# I2C3 register map
Vendor: Texas Instruments
Peripheral module from a debugger description file (folder TDA2Px).
Registers are 16-bit, access per field, reset 0x0 unless marked. A register's access mark holds for its fields unless they carry their own. Offsets are as the file gives them; lines under a group give offsets from that group; [hi:lo] are bit positions; {n}, {i} and the like mark numbered series; 'fields as' and 'values as' point back to an identical list; <NAME> marks a mode.

## I2C3
0x00 I2C_REVNB_LO ro reset not defined — Module Revision Identifier Used by software to track features, bugs, and compatibility
  [15:0] REVISION — IP Revision
0x04 I2C_REVNB_HI ro reset not defined — Module Revision Identifeir Used by software to track features, bugs, and compatibility
  [15:0] REVISION — IP Revision
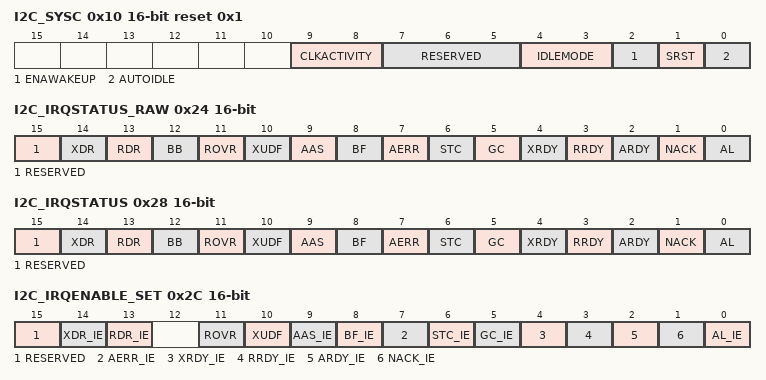
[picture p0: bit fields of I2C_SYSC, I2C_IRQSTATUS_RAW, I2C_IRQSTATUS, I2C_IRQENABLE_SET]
0x10 I2C_SYSC reset 0x1 — System Configuration register
  [9:8] CLKACTIVITY rw — Clock Activity selection bits
    0=boothoff (Both clocks can be cut off); 1=ocpon (Only OCP clock must be kept active; system clock can be cut off); 2=boothon (Only system clock must be kept active; OCP clock can be cut off); 3=syson (Both clocks must be kept active)
  [7:5] RESERVED ro — Reads return 0.
  [4:3] IDLEMODE rw — Idle Mode selection bits
    0=smartidle (Force Idle mode); 1=smartidle_wakeup (No Idle mode); 2=smartidle_wakeup (Smart Idle mode); 3=Smart-idle wakeup-capable mode
  [2] ENAWAKEUP rw — Enable Wakeup control bit
    0=disable (Wakeup mechanism is disabled); 1=enable (Wakeup mechanism is enabled)
  [1] SRST rw — SoftReset bit
    0=nmode (Normal mode); 1=rstmode (The module is reset)
  [0] AUTOIDLE rw — Autoidle bit
    0=disable (Auto Idle mechanism is disabled); 1=enable (Auto Idle mechanism is enabled)
0x20 I2C_EOI — End Of Interrupt number specification
  [0] LINE_NUMBER wo — Software End Of Interrupt (EOI) control. Write number of interrupt output.
0x24 I2C_IRQSTATUS_RAW — Per-event raw interrupt status vector. The raw status is set even if event is not enabled. Write 1 to set the (raw) status. Used mostly for debug
  [15] RESERVED rw — Write 0s for future compatibility. Read returns 0.
  [14] XDR rw — Transmit draining IRQ status.
    0=clear (Transmit draining inactive.); 1=set (Transmit draining enabled.)
  [13] RDR rw — Receive draining IRQ status.
    0=clear (Receive draining inactive.); 1=set (Receive draining enabled.)
  [12] BB ro — Bus busy status. Writing into this bit has no effect.
    1=set (Bus is occupied.); 0=clear (Bus is free.)
  [11] ROVR rw — Receive overrun status. Writing into this bit has no effect.
    1=set (Receiver overrun.); 0=clear (Normal operation.)
  [10] XUDF rw — Transmit underflow status. Writing into this bit has no effect.
    1=set (Transmit underflow.); 0=clear (Normal operation.)
  [9] AAS rw — Address recognized as slave IRQ status.
    0=clear (No action.); 1=set (Address recognized.)
  [8] BF rw — Bus Free IRQ status.
    0=clear (No action.); 1=set (Bus Free.)
  [7] AERR rw — Access Error IRQ status.
    0=clear (No action.); 1=set (Access Error.)
  [6] STC rw — Start Condition IRQ status.
    0=clear (No action.); 1=set (Start Condition detected.)
  [5] GC rw — General call IRQ status. Set to 1 by core when General call address detected and interrupt signaled to IRQ_Crossbar.
    0=clear (No general call detected.); 1=set (General call address detected.)
  [4] XRDY rw — Transmit data ready IRQ status. Set to 1 by core when transmitter and when new data is requested. When set to 1 by core, an interrupt is signaled to IRQ_Crossbar.
    0=clear (Transmision ongoing.); 1=set (Transmit data ready.)
  [3] RRDY rw — Receive data ready IRQ status. Set to 1 by core when receiver mode, a new data is able to be read. When set to 1 by core, an interrupt is signaled to IRQ_Crossbar.
    0=clear (No data available.); 1=set (Receive data available.)
  [2] ARDY rw — Register access ready IRQ status. When set to 1 it indicates that previous access has been performed and registers are ready to be accessed again. An interrupt is signaled to IRQ_Crossbar.
    0=clear (Module busy.); 1=set (Access ready.)
  [1] NACK rw — No acknowledgement IRQ status. Bit is set when No Acknowledge has been received, an interrupt is signaled to IRQ_Crossbar.
    0=clear (Normal operation.); 1=set (Not Acknowledge detected.)
  [0] AL rw — Arbitration lost IRQ status. This bit is automatically set by the hardware when it loses the Arbitration in master transmit mode, an interrupt is signaled to IRQ_Crossbar. During reads, it always returns 0.
    0=clear (Normal operation.); 1=set (Arbitration lost detected.)
0x28 I2C_IRQSTATUS access not given — Per-event enabled interrupt status vector
  [15] RESERVED rw — Write 0s for future compatibility. Read returns 0.
  [14] XDR — Transmit draining IRQ enabled status. (access RW W1toClr)
    values as I2C_IRQSTATUS_RAW.XDR
  [13] RDR — Receive draining IRQ enabled status. (access RW W1toClr)
    values as I2C_IRQSTATUS_RAW.RDR
  [12] BB ro — Bus busy enabled status. Writing into this bit has no effect.
    1=set (Bus is occupied.); 0=clear (Bus is free.)
  [11] ROVR — Receive overrun enabled status. Writing into this bit has no effect. (access RW W1toClr)
    1=set (Receiver overrun.); 0=clear (Normal operation.)
  [10] XUDF — Transmit underflow enabled status. Writing into this bit has no effect. (access RW W1toClr)
    1=set (Transmit underflow.); 0=clear (Normal operation.)
  [9] AAS — Address recognized as slave IRQ enabled status. (access RW W1toClr)
    0=clear (No action.); 1=set (Address recognized.)
  [8] BF — Bus Free IRQ enabled status. (access RW W1toClr)
    0=clear (No action.); 1=set (Bus Free.)
  [7] AERR — Access Error IRQ enabled status. (access RW W1toClr)
    0=clear (No action.); 1=set (Access Error.)
  [6] STC — Start Condition IRQ enabled status. (access RW W1toClr)
    0=clear (No action.); 1=set (Start Condition detected.)
  [5] GC — General call IRQ enabled status. Set to 1 by core when General call address detected and interrupt signaled to IRQ_Crossbar. Write 1 to clear. (access RW W1toClr)
    values as I2C_IRQSTATUS_RAW.GC
  [4] XRDY — Transmit data ready IRQ enabled status. Set to 1 by core when transmitter and when new data is requested. When set to 1 by core, an interrupt is signaled to IRQ_Crossbar. Write 1 to clear. (access RW W1toClr)
    0=clear (Transmision ongoing.); 1=set (Transmit data ready.)
  [3] RRDY — Receive data ready IRQ enabled status. Set to 1 by core when receiver mode, a new data is able to be read. When set to 1 by core, an interrupt is signaled to IRQ_Crossbar. Write 1 to clear. (access RW W1toClr)
    values as I2C_IRQSTATUS_RAW.RRDY
  [2] ARDY — Register access ready IRQ enabled status. When set to 1 it indicates that previous access has been performed and registers are ready to be accessed again. An interrupt is signaled to IRQ_Crossbar. Write 1 to clear. (access RW W1toClr)
    0=clear (Module busy.); 1=set (Access ready.)
  [1] NACK — No acknowledgement IRQ enabled status. Bit is set when No Acknowledge has been received, an interrupt is signaled to IRQ_Crossbar. Write 1 to clear this bit. (access RW W1toClr)
    values as I2C_IRQSTATUS_RAW.NACK
  [0] AL — Arbitration lost IRQ enabled status. This bit is automatically set by the hardware when it loses the Arbitration in master transmit mode, an interrupt is signaled to IRQ_Crossbar. During reads, it always returns 0. (access RW W1toClr)
    values as I2C_IRQSTATUS_RAW.AL
0x2C I2C_IRQENABLE_SET access not given — Per-event interrupt enable bit vector.
  [15] RESERVED ro — Write 0s for future compatibility. Read returns 0.
  [14] XDR_IE — Transmit Draining interrupt enable set. Unmask the interrupt signaled by bit inI2C_IRQSTATUS_RAW[XDR].Read: enum=disable . Write: enum=enable . (access RW W1toSet)
    0=disable (Transmit Draining interrupt disabled); 1=enable (Transmit Draining interrupt enabled); 0=enable (Has no effect); 1=Enables the Transmit Draining interrupt
  [13] RDR_IE — Receive Draining interrupt enable set. Unmask the interrupt signaled by bit inI2C_IRQSTATUS_RAW [RDR].Read: enum=disable . Write: enum=enable . (access RW W1toSet)
    0=disable (Receive Draining interrupt disabled); 1=enable (Receive Draining interrupt enabled); 0=enable (Has no effect); 1=Enables the Receive Draining interrupt
  [11] ROVR — Receive overrun enable set.Read: enum=disable . Write: enum=enable . (access RW W1toSet)
    0=disable (Receive overrun interrupt disabled); 1=enable (Receive overrun interrupt enabled); 0=enable (Has no effect); 1=Enables the Receive overrun interrupt
  [10] XUDF — Transmit underflow enable set.Read: enum=disable . Write: enum=enable . (access RW W1toSet)
    0=disable (Transmit underflow interrupt disabled); 1=enable (Transmit underflow interrupt enabled); 0=enable (Has no effect); 1=Enables the Transmit underflow interrupt
  [9] AAS_IE — Addressed as Slave interrupt enable set. Unmask the interrupt signaled by bit inI2C_IRQSTATUS_RAW [AAS].Read: enum=disable . Write: enum=enable . (access RW W1toSet)
    0=disable (Addressed as Slave interrupt disabled); 1=enable (Addressed as Slave interrupt enabled); 0=enable (Has no effect); 1=Enables the Addressed as Slave interrupt
  [8] BF_IE — Bus Free interrupt enable set. Unmask the interrupt signaled by bit inI2C_IRQSTATUS_RAW [BF].Read: enum=disable . Write: enum=enable . (access RW W1toSet)
    0=disable (Bus Free interrupt disabled); 1=enable (Bus Free interrupt enabled); 0=enable (Has no effect); 1=Enables the Bus Free interrupt
  [7] AERR_IE — Access Error interrupt enable set. Unmask the interrupt signaled by bit inI2C_IRQSTATUS_RAW [AERR].Read: enum=disable . Write: enum=enable . (access RW W1toSet)
    0=disable (Access Error interrupt disabled); 1=enable (Access Error interrupt enabled); 0=enable (Has no effect); 1=Enables the Access Error interrupt
  [6] STC_IE — Start Condition interrupt enable set. Unmask the interrupt signaled by bit inI2C_IRQSTATUS_RAW [STC].Read: enum=disable . Write: enum=enable . (access RW W1toSet)
    0=disable (Start Condition interrupt disabled); 1=enable (Start Condition interrupt enabled); 0=enable (Has no effect); 1=Enables the Start Condition interrupt
  [5] GC_IE — General call Interrupt enable set. Unmask the interrupt signaled by bit inI2C_IRQSTATUS_RAW [GC]Read: enum=disable . Write: enum=enable . (access RW W1toSet)
    0=disable (General call interrupt disabled); 1=enable (General call interrupt enabled); 0=enable (Has no effect); 1=Enables the General call interrupt
  [4] XRDY_IE — Transmit data ready interrupt enable set. Unmask the interrupt signaled by bit inI2C_IRQSTATUS_RAW [XRDY]Read: enum=disable . Write: enum=enable . (access RW W1toSet)
    0=disable (Transmit data ready interrupt disabled); 1=enable (Transmit data ready interrupt enabled); 0=enable (Has no effect); 1=Enables the Transmit data ready interrupt
  [3] RRDY_IE — Receive data ready interrupt enable set. Unmask the interrupt signaled by bit in I2C_IRQSTTUS_RAW [RRDY]Read: enum=disable . Write: enum=enable . (access RW W1toSet)
    0=disable (Receive data ready interrupt disabled); 1=enable (Receive data ready interrupt enabled); 0=enable (Has no effect); 1=Enables the Receive data ready interrupt
  [2] ARDY_IE — Register access ready interrupt enable set. Unmask the interrupt signaled by bit inI2C_IRQSTATUS_RAW [ARDY]Read: enum=disable . Write: enum=enable . (access RW W1toSet)
    0=disable (Register access ready interrupt disabled); 1=enable (Register access ready interrupt enabled); 0=enable (Has no effect); 1=Enables the Register access ready interrupt
  [1] NACK_IE — No acknowledgement interrupt enable set. Unmask the interrupt signaled by bit inI2C_IRQSTATUS_RAW [NACK]Read: enum=disable . Write: enum=enable . (access RW W1toSet)
    0=disable (Not Acknowledge interrupt disabled); 1=enable (Not Acknowledge interrupt enabled); 0=enable (Has no effect); 1=Enables the Not Acknowledge interrupt
  [0] AL_IE — Arbitration lost interrupt enable set. Unmask the interrupt signaled by bit inI2C_IRQSTATUS_RAW [AL]Read: enum=disable . Write: enum=enable . (access RW W1toSet)
    0=disable (Arbitration lost interrupt disabled); 1=enable (Arbitration lost interrupt enabled); 0=enable (Has no effect); 1=Enables the Arbitration lost interrupt
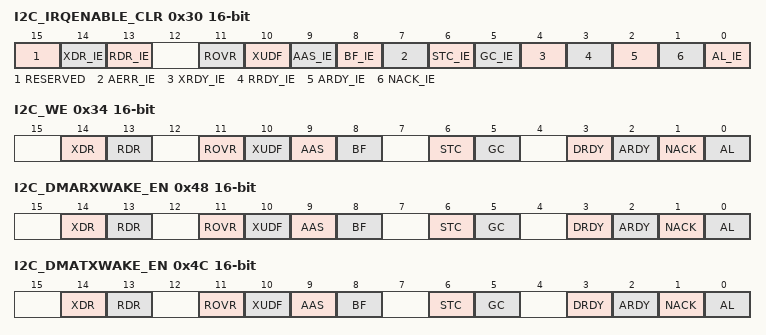
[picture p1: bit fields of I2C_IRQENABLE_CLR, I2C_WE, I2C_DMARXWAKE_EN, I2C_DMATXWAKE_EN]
0x30 I2C_IRQENABLE_CLR access not given — Per-event interrupt clear bit vector.
  [15] RESERVED ro — Write 0s for future compatibility. Read returns 0.
  [14] XDR_IE — Transmit Draining interrupt enable clear. Mask the interrupt signaled by bit inI2C_IRQSTATUS_RAW [XDR].Read: enum=disable . Write: enum=enable . (access RW W1toClr)
    0=disable (Transmit Draining interrupt disabled); 1=enable (Transmit Draining interrupt enabled); 0=enable (Has no effect); 1=enable (Disables the Transmit Draining interrupt)
  [13] RDR_IE — Receive Draining interrupt enable clear. Mask the interrupt signaled by bit in I2C_IRQSTAUS_RAW [RDR].Read: enum=disable . Write: enum=enable . (access RW W1toClr)
    0=disable (Receive Draining interrupt disabled); 1=enable (Receive Draining interrupt enabled); 0=enable (Has no effect); 1=enable (Disables the Receive Draining interrupt)
  [11] ROVR — Receive overrun enable clear.Read: enum=disable . Write: enum=enable . (access RW W1toClr)
    0=disable (Receive overrun interrupt disabled); 1=enable (Receive overrun interrupt enabled); 0=enable (Has no effect); 1=enable (Disables the Receive overrun interrupt)
  [10] XUDF — Transmit underflow enable clear.Read: enum=disable . Write: enum=enable . (access RW W1toClr)
    0=disable (Transmit underflow interrupt disabled); 1=enable (Transmit underflow interrupt enabled); 0=enable (Has no effect); 1=enable (Disables the Transmit underflow interrupt)
  [9] AAS_IE — Addressed as Slave interrupt enable clear. Mask the interrupt signaled by bit inI2C_IRQSTATUS_RAW [AAS].Read: enum=disable . Write: enum=enable . (access RW W1toClr)
    0=disable (Addressed as Slave interrupt disabled); 1=enable (Addressed as Slave interrupt enabled); 0=enable (Has no effect); 1=enable (Disables the Addressed as Slave interrupt)
  [8] BF_IE — Bus Free interrupt enable clear. Mask the interrupt signaled by bit inI2C_IRQSTATUS_RAW [BF].Read: enum=disable . Write: enum=enable . (access RW W1toClr)
    0=disable (Bus Free interrupt disabled); 1=enable (Bus Free interrupt enabled); 0=enable (Has no effect); 1=enable (Disables the Bus Free interrupt)
  [7] AERR_IE — Access Error interrupt enable clear. Mask the interrupt signaled by bit inI2C_IRQSTATUS_RAW [AERR].Read: enum=disable . Write: enum=enable . (access RW W1toClr)
    0=disable (Access Error interrupt disabled); 1=enable (Access Error interrupt enabled); 0=enable (Has no effect); 1=enable (Disables the Access Error interrupt)
  [6] STC_IE — Start Condition interrupt enable clear. Mask the interrupt signaled by bit inI2C_IRQSTATUS_RAW [STC].Read: enum=disable . Write: enum=enable . (access RW W1toClr)
    0=disable (Start Condition interrupt disabled); 1=enable (Start Condition interrupt enabled); 0=enable (Has no effect); 1=enable (Disables the Start Condition interrupt)
  [5] GC_IE — General call Interrupt enable clear. Mask the interrupt signaled by bit inI2C_IRQSTATUS_RAW [GC]Read: enum=disable . Write: enum=enable . (access RW W1toClr)
    0=disable (General call interrupt disabled); 1=enable (General call interrupt enabled); 0=enable (Has no effect); 1=enable (Disables the General call interrupt)
  [4] XRDY_IE — Transmit data ready interrupt enable clear. Mask the interrupt signaled by bit inI2C_IRQSTATUS_RAW [XRDY]Read: enum=disable . Write: enum=enable . (access RW W1toClr)
    0=disable (Transmit data ready interrupt disabled); 1=enable (Transmit data ready interrupt enabled); 0=enable (Has no effect); 1=enable (Disables the Transmit data ready interrupt)
  [3] RRDY_IE — Receive data ready interrupt enable clear. Mask the interrupt signaled by bit in I2C_IRQSTAUS_RAW [RRDY]Read: enum=disable . Write: enum=enable . (access RW W1toClr)
    0=disable (Receive data ready interrupt disabled); 1=enable (Receive data ready interrupt enabled); 0=enable (Has no effect); 1=enable (Disables the Receive data ready interrupt)
  [2] ARDY_IE — Register access ready interrupt enable clear. Mask the interrupt signaled by bit inI2C_IRQSTATUS_RAW [ARDY]Read: enum=disable . Write: enum=enable . (access RW W1toClr)
    0=disable (Register access ready interrupt disabled); 1=enable (Register access ready interrupt enabled); 0=enable (Has no effect); 1=enable (Disables the Register access ready interrupt)
  [1] NACK_IE — No acknowledgement interrupt enable clear. Mask the interrupt signaled by bit inI2C_IRQSTATUS_RAW [NACK]Read: enum=disable . Write: enum=enable . (access RW W1toClr)
    0=disable (Not Acknowledge interrupt disabled); 1=enable (Not Acknowledge interrupt enabled); 0=enable (Has no effect); 1=enable (Disables the Not Acknowledge interrupt)
  [0] AL_IE — Arbitration lost interrupt enable clear. Mask the interrupt signaled by bit inI2C_IRQSTATUS_RAW[AL]Read: enum=disable . Write: enum=enable . (access RW W1toClr)
    0=disable (Arbitration lost interrupt disabled); 1=enable (Arbitration lost interrupt enabled); 0=enable (Has no effect); 1=enable (Disables the Arbitration lost interrupt)
0x34 I2C_WE — I2C wakeup enable vector.
  [14] XDR rw — Transmit Draining wakeup set.
    0=disable (Transmit draining wakeup disabled); 1=enable (Transmit draining wakeup enabled)
  [13] RDR rw — Receive Draining wakeup set.
    0=disable (Receive draining wakeup disabled); 1=enable (Receive draining wakeup enabled)
  [11] ROVR rw — Receive overrun wakeup set.
    0=disable (Receive overrun wakeup disabled); 1=enable (Receive overrun wakeup enabled)
  [10] XUDF rw — Transmit underflow wakeup set.
    0=disable (Transmit underflow wakeup disabled); 1=enable (Transmit underflow wakeup enabled)
  [9] AAS rw — Address as slave IRQ wakeup set.
    0=disable (Addressed as slave wakeup disabled); 1=enable (Addressed as slave wakeup enabled)
  [8] BF rw — Bus Free IRQ wakeup set.
    0=disable (Bus Free wakeup disabled); 1=enable (Bus Free wakeup enabled)
  [6] STC rw — Start Condition IRQ wakeup set.
    0=disable (Start condition wakeup disabled); 1=enable (Start condition wakeup enabled)
  [5] GC rw — General call IRQ wakeup set.
    0=disable (General call wakeup disabled); 1=enable (General call wakeup enabled)
  [3] DRDY rw — Receive/Transmit data ready IRQ wakeup set.
    0=disable (Transmit/receive data ready wakeup disabled); 1=enable (Transmit/receive data ready wakeup enabled)
  [2] ARDY rw — Register access ready IRQ wakeup set.
    0=disable (Register access ready wakeup disabled); 1=enable (Register access ready wakeup enabled)
  [1] NACK rw — No acknowledgment IRQ wakeup set.
    0=disable (Not Acknowledge wakeup disabled); 1=enable (Not Acknowledge wakeup enabled)
  [0] AL rw — Arbitration lost IRQ wakeup set.
    0=disable (Arbitration lost wakeup disabled); 1=enable (Arbitration lost wakeup enabled)
0x38 I2C_DMARXENABLE_SET — Per-event DMA RX enable set.
  [0] DMARX_ENABLE_SET rw — Receive DMA channel enable set.
0x3C I2C_DMATXENABLE_SET — Per-event DMA TX enable set.
  [0] DMATX_ENABLE_SET rw — Transmit DMA channel enable set.
0x40 I2C_DMARXENABLE_CLR — Per-event DMA RX enable clear.
  [0] DMARX_ENABLE_CLEAR rw — Receive DMA channel enable clear.
0x44 I2C_DMATXENABLE_CLR — Per-event DMA TX enable clear.
  [0] DMATX_ENABLE_CLEAR rw — Transmit DMA channel enable clear.
0x48 I2C_DMARXWAKE_EN — Per-event DMA RX wakeup enable.
  fields as I2C_WE
0x4C I2C_DMATXWAKE_EN — Per-event DMA TX wakeup enable.
  fields as I2C_WE
0x90 I2C_SYSS reset 0x1 — System Status register
  [0] RDONE rw — Reset done bit
    1=rstcomp (Reset completed); 0=rstongoing (Internal module reset in on-going)
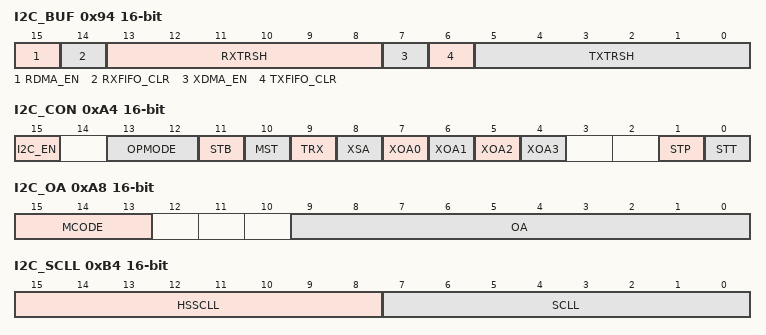
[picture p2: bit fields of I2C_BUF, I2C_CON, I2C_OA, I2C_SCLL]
0x94 I2C_BUF rw — Buffer Configuration register
  [15] RDMA_EN — Receive DMA channel enable
    0=disable (Receive DMA channel disabled); 1=enable (Receive DMA channel enabled)
  [14] RXFIFO_CLR — Receive FIFO clear
    0=nmode (Normal mode); 1=rstmode (Rx FIFO is reset)
  [13:8] RXTRSH — Threshold value for FIFO buffer in RX mode
  [7] XDMA_EN — Transmit DMA channel enable
    0=disable (Transmit DMA channel disabled); 1=enable (Transmit DMA channel enabled)
  [6] TXFIFO_CLR — Transmit FIFO clear
    0=nmode (Normal mode); 1=rstmode (Tx FIFO is reset)
  [5:0] TXTRSH — Threshold value for FIFO buffer in TX mode
0x98 I2C_CNT rw — Data counter register
  [15:0] DCOUNT — Data count
0x9C I2C_DATA (reset mask 0xFF00) — Data access register
  [7:0] DATA rw — Transmit/Receive data FIFO endpoint
0xA4 I2C_CON — I2C configuration register.
  [15] I2C_EN rw — I2C module enable.
    0=disable (Controller in reset. FIFO are cleared and status bits are set to their default value); 1=enable (Module enabled)
  [13:12] OPMODE rw — Operation mode selection.
    0=fsi2c (I2C Fast/Standard mode.); 1=hsi2c (I2C High Speed mode.); 2=sccb (Reserved)
  [11] STB rw — Start byte mode (master mode only).
    0=Normal mode; 1=stb (Start byte mode)
  [10] MST rw — Master/slave mode.
    0=slv (Slave mode); 1=mst (Master mode)
  [9] TRX rw — Transmitter/Receiver mode (master mode only).
    0=rcv (Receiver mode); 1=trx (Transmitter mode)
  [8] XSA rw — Expand Slave address.
    0=b07 (7-bit address mode); 1=b10 (10-bit address mode)
  [7-n] XOA{n} rw (n=0..3) — Expand Own address {n}.
    0=b07 (7-bit address mode); 1=b10 (10-bit address mode)
  [1] STP rw — Stop condition (master mode only).
    0=nstp (No action or stop condition detected); 1=stp (Stop condition queried)
  [0] STT rw — Start condition (master mode only).
    0=nstt (No action or start condition detected); 1=stt (Start condition queried)
0xA8 I2C_OA — Own address register
  [15:13] MCODE rw — Master Code
  [9:0] OA rw — Own address
0xAC I2C_SA reset 0x3FF — Slave address register
  [9:0] SA rw — Slave address
0xB0 I2C_PSC — I2C Clock Prescaler Register
  [7:0] PSC rw — Fast/Standard mode prescale sampling clock divider value 0x0: Divide by 1 0x1: Divide by 2 .............................. 0xFF: Divide by 256
0xB4 I2C_SCLL rw — I2C SCL Low Time Register.
  [15:8] HSSCLL — High speed mode SCL low timeThe value of the bit field is automatically increased by 7. .
  [7:0] SCLL — Fast/standard mode SCL low timeThe value of the bit field is automatically increased by 7. .
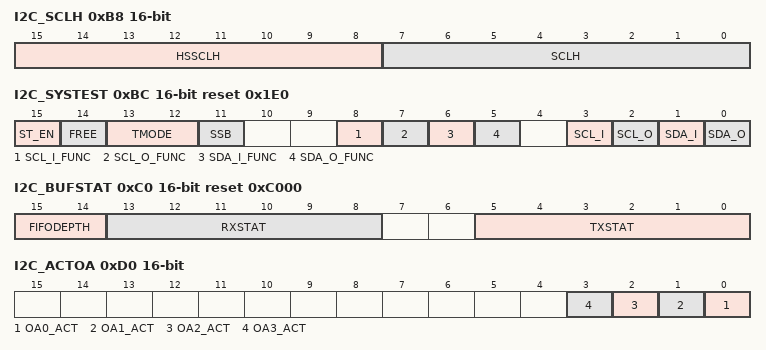
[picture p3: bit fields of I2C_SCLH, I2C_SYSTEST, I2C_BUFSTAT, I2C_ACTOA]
0xB8 I2C_SCLH rw — I2C SCL High Time Register.
  [15:8] HSSCLH — High speed mode SCL high timeThe value of the bit field is automatically increased by 5. .
  [7:0] SCLH — Fast/standard mode SCL high timeThe value of the bit field is automatically increased by 5. .
0xBC I2C_SYSTEST reset 0x1E0 — I2C System Test Register.
  [15] ST_EN rw — System test enable.
    0=disable (Normal mode. All others bits in register are read only); 1=enable (System test enabled. Permit other system test registers bits to be set)
  [14] FREE rw — Free running mode (on breakpoint)
    0=Stop mode (on breakpoint condition). If Master mode, it stops after completion of the ongoing bit transfer. In slave mode, it stops during the phase transfer when 1 byte is completely transmitted/received.; 1=Free running mode
  [13:12] TMODE rw — Test mode select.
    0=Functional mode (default); 3=Loop back mode select + SDA/SCL IO mode select; 2=Test of SCL counters (SCLL, SCLH, PSC). SCL provides a permanent clock with master mode.
  [11] SSB rw — Set all status bits inI2C_IRQSTATUS_RAW [14:0].
    0=noaction; 1=setstatus (Set interrupt status bits to 1.)
  [8] SCL_I_FUNC ro — SCL line input value (functional mode).
    1=sclih (Read 1 from SCL line); 0=sclil (Read 0 from SCL line)
  [7] SCL_O_FUNC ro — SCL line output value (functional mode).
    1=sclih (Driven 1 on SCL line); 0=sclil (Driven 0 on SCL line)
  [6] SDA_I_FUNC ro — SDA line input value (functional mode).
    1=sdaih (Read 1 from SDA line); 0=sdail (Read 0 from SDA line)
  [5] SDA_O_FUNC ro — SDA line output value (functional mode).
    1=sdaoh (Driven 1 to SDA line); 0=sdaol (Driven 0 to SDA line)
  [3] SCL_I ro — SCL line sense input value
    values as SCL_I_FUNC
  [2] SCL_O rw — SCL line drive output value.
    0=sclol (Write 0 to SCL line); 1=scloh (Write 1 to SCL line)
  [1] SDA_I ro — SDA line sense input value.
    values as SDA_I_FUNC
  [0] SDA_O rw — SDA line drive output value.
    0=sdaol (Write 0 to SDA line); 1=sdaoh (Write 1 to SDA line)
0xC0 I2C_BUFSTAT ro reset 0xC000 — I2C Buffer Status Register.
  [15:14] FIFODEPTH — Internal FIFO buffers depth.
    0=8-bytes_FIFO; 1=16-bytes_FIFO; 2=32-bytes_FIFO; 3=64-bytes_FIFO
  [13:8] RXSTAT — RX Buffer Status
  [5:0] TXSTAT — TX Buffer Status.
{0xC0+4i} I2C_OA{i} (i=1..3) — I2C Own Address {i} Register
  [9:0] OA{i} rw — Own address {i}
0xD0 I2C_ACTOA ro — I2C Active Own Address Register.
  [all] fields
    1=active (Own Address active.); 0=inactive (Own Address inactive.)
  [n] OA{n}_ACT (n=0..3) — Own Address {n} active.
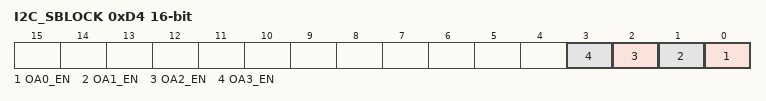
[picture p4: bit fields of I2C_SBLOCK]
0xD4 I2C_SBLOCK — I2C Clock Blocking Enable Register.
  [all] fields
    0=unlock (I2C Clock Released.); 1=lock (I2C Clock Blocked.)
  [n] OA{n}_EN rw (n=0..3) — Enable I2C Clock Blocking for Own Address {n}.
